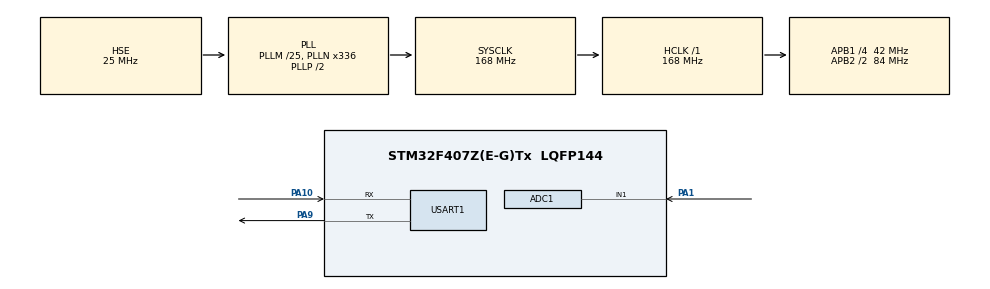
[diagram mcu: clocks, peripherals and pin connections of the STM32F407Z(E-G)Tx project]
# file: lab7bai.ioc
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ADC1.Channel-0\#ChannelRegularConversion=ADC_CHANNEL_1
ADC1.NbrOfConversionFlag=1
ADC1.Rank-0\#ChannelRegularConversion=1
ADC1.SamplingTime-0\#ChannelRegularConversion=ADC_SAMPLETIME_480CYCLES
ADC1.master=1
Mcu.Family=STM32F4
Mcu.Name=STM32F407Z(E-G)Tx
Mcu.Package=LQFP144
NVIC.PriorityGroup=NVIC_PRIORITYGROUP_4
PA1.Signal=ADCx_IN1
PA10.Mode=Asynchronous
PA10.Signal=USART1_RX
PA9.Mode=Asynchronous
PA9.Signal=USART1_TX
PH0-OSC_IN.Mode=HSE-External-Oscillator
PH0-OSC_IN.Signal=RCC_OSC_IN
PH1-OSC_OUT.Mode=HSE-External-Oscillator
PH1-OSC_OUT.Signal=RCC_OSC_OUT
ProjectManager.HeapSize=0x200
ProjectManager.StackSize=0x400
ProjectManager.TargetToolchain=STM32CubeIDE
RCC.48MHZClocksFreq_Value=84000000
RCC.AHBFreq_Value=168000000
RCC.APB1CLKDivider=RCC_HCLK_DIV4
RCC.APB1Freq_Value=42000000
RCC.APB1TimFreq_Value=84000000
RCC.APB2CLKDivider=RCC_HCLK_DIV2
RCC.APB2Freq_Value=84000000
RCC.APB2TimFreq_Value=168000000
RCC.CortexFreq_Value=168000000
RCC.HCLKFreq_Value=168000000
RCC.HSE_VALUE=25000000
RCC.HSI_VALUE=16000000
RCC.LSE_VALUE=32768
RCC.PLLM=25
RCC.PLLN=336
RCC.PLLSourceVirtual=RCC_PLLSOURCE_HSE
RCC.SYSCLKFreq_VALUE=168000000
RCC.SYSCLKSource=RCC_SYSCLKSOURCE_PLLCLK
RCC.VCOOutputFreq_Value=336000000
SH.ADCx_IN1.0=ADC1_IN1,IN1
USART1.VirtualMode=VM_ASYNC
board=custom

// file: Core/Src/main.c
/* USER CODE BEGIN Header */
/**
  ******************************************************************************
  * @file           : main.c
  * @brief          : Main program body
  ******************************************************************************
  * @attention
  *
  * Copyright (c) 2026 STMicroelectronics.
  * All rights reserved.
  *
  * This software is licensed under terms that can be found in the LICENSE file
  * in the root directory of this software component.
  * If no LICENSE file comes with this software, it is provided AS-IS.
  *
  ******************************************************************************
  */
/* USER CODE END Header */
#include "main.h"

/* USER CODE BEGIN Includes */
#include <stdio.h>
#include <string.h>
/* USER CODE END Includes */

/* USER CODE BEGIN PD */
  #define VREF       3.3f
  #define ADC_MAX    4095.0f
/* USER CODE END PD */

ADC_HandleTypeDef hadc1;

UART_HandleTypeDef huart1;

void SystemClock_Config(void);
static void MX_GPIO_Init(void);
static void MX_ADC1_Init(void);
static void MX_USART1_UART_Init(void);

/* USER CODE BEGIN 0 */
// Redirect printf to USART2
int __io_putchar(int ch)
{
    HAL_UART_Transmit(&huart1, (uint8_t *)&ch, 1, HAL_MAX_DELAY);
    return ch;
}
/* USER CODE END 0 */

int main(void)
{

  /* MCU Configuration--------------------------------------------------------*/

  /* Reset of all peripherals, Initializes the Flash interface and the Systick. */
	HAL_Init();

  /* Configure the system clock */
  SystemClock_Config();

  /* Initialize all configured peripherals */
  MX_GPIO_Init();
  MX_ADC1_Init();
  MX_USART1_UART_Init();
  /* USER CODE BEGIN 2 */
#define SCALE_INV  1.9960f
  uint32_t adc_raw = 0;
  float v_adc_in  = 0.0f;
  float v_bat     = 0.0f;

  // Voltage divider scale factor
  // With R1 = R2 = 1 MOhm, scale = R2/(R1+R2) = 0.5
  // So to recover original voltage: multiply by (R1+R2)/R2 = 2.0
  // ADC reference voltage

   // = (R1+R2)/R2, update in step 7#define SCALE_INV  2.0f
  /* USER CODE END 2 */

  /* Infinite loop */
  while (1)
  {

    /* USER CODE BEGIN 3 */
	  while (1)
	  {
	      // ===== STEPS 4, 8, 9 — Single conversion =====
	      HAL_ADC_Start(&hadc1);
	      HAL_ADC_PollForConversion(&hadc1, HAL_MAX_DELAY);
	      adc_raw = HAL_ADC_GetValue(&hadc1);
	      HAL_ADC_Stop(&hadc1);

	      v_adc_in = ((float)adc_raw / ADC_MAX) * VREF;
	      v_bat    = v_adc_in * SCALE_INV;  // <-- BREAKPOINT HERE for steps 4,8,9

	      // ===== STEPS 10, 11, 12 — Averaging (comment out above, uncomment this) =====

		  uint32_t sum = 0;
		    for (int i = 0; i < 10; i++)
		    {
		        HAL_ADC_Start(&hadc1);
		        HAL_ADC_PollForConversion(&hadc1, HAL_MAX_DELAY);
		        sum += HAL_ADC_GetValue(&hadc1);
		        HAL_ADC_Stop(&hadc1);
		        HAL_Delay(10);
		    }
		    adc_raw  = sum / 10;
		    v_adc_in = ((float)adc_raw / ADC_MAX) * VREF;
		    v_bat    = v_adc_in * SCALE_INV;

		    HAL_Delay(500);
	  }
  }
  /* USER CODE END 3 */
}

void SystemClock_Config(void)
{
  RCC_OscInitTypeDef RCC_OscInitStruct = {0};
  RCC_ClkInitTypeDef RCC_ClkInitStruct = {0};

  /** Configure the main internal regulator output voltage
  */
  __HAL_RCC_PWR_CLK_ENABLE();
  __HAL_PWR_VOLTAGESCALING_CONFIG(PWR_REGULATOR_VOLTAGE_SCALE1);

  /** Initializes the RCC Oscillators according to the specified parameters
  * in the RCC_OscInitTypeDef structure.
  */
  RCC_OscInitStruct.OscillatorType = RCC_OSCILLATORTYPE_HSE;
  RCC_OscInitStruct.HSEState = RCC_HSE_ON;
  RCC_OscInitStruct.PLL.PLLState = RCC_PLL_ON;
  RCC_OscInitStruct.PLL.PLLSource = RCC_PLLSOURCE_HSE;
  RCC_OscInitStruct.PLL.PLLM = 25;
  RCC_OscInitStruct.PLL.PLLN = 336;
  RCC_OscInitStruct.PLL.PLLP = RCC_PLLP_DIV2;
  RCC_OscInitStruct.PLL.PLLQ = 4;
  if (HAL_RCC_OscConfig(&RCC_OscInitStruct) != HAL_OK)
  {
    Error_Handler();
  }

  /** Initializes the CPU, AHB and APB buses clocks
  */
  RCC_ClkInitStruct.ClockType = RCC_CLOCKTYPE_HCLK|RCC_CLOCKTYPE_SYSCLK
                              |RCC_CLOCKTYPE_PCLK1|RCC_CLOCKTYPE_PCLK2;
  RCC_ClkInitStruct.SYSCLKSource = RCC_SYSCLKSOURCE_PLLCLK;
  RCC_ClkInitStruct.AHBCLKDivider = RCC_SYSCLK_DIV1;
  RCC_ClkInitStruct.APB1CLKDivider = RCC_HCLK_DIV4;
  RCC_ClkInitStruct.APB2CLKDivider = RCC_HCLK_DIV2;

  if (HAL_RCC_ClockConfig(&RCC_ClkInitStruct, FLASH_LATENCY_5) != HAL_OK)
  {
    Error_Handler();
  }
}

static void MX_ADC1_Init(void)
{

  ADC_ChannelConfTypeDef sConfig = {0};

  /** Configure the global features of the ADC (Clock, Resolution, Data Alignment and number of conversion)
  */
  hadc1.Instance = ADC1;
  hadc1.Init.ClockPrescaler = ADC_CLOCK_SYNC_PCLK_DIV4;
  hadc1.Init.Resolution = ADC_RESOLUTION_12B;
  hadc1.Init.ScanConvMode = DISABLE;
  hadc1.Init.ContinuousConvMode = DISABLE;
  hadc1.Init.DiscontinuousConvMode = DISABLE;
  hadc1.Init.ExternalTrigConvEdge = ADC_EXTERNALTRIGCONVEDGE_NONE;
  hadc1.Init.ExternalTrigConv = ADC_SOFTWARE_START;
  hadc1.Init.DataAlign = ADC_DATAALIGN_RIGHT;
  hadc1.Init.NbrOfConversion = 1;
  hadc1.Init.DMAContinuousRequests = DISABLE;
  hadc1.Init.EOCSelection = ADC_EOC_SINGLE_CONV;
  if (HAL_ADC_Init(&hadc1) != HAL_OK)
  {
    Error_Handler();
  }

  /** Configure for the selected ADC regular channel its corresponding rank in the sequencer and its sample time.
  */
  sConfig.Channel = ADC_CHANNEL_1;
  sConfig.Rank = 1;
  sConfig.SamplingTime = ADC_SAMPLETIME_480CYCLES;
  if (HAL_ADC_ConfigChannel(&hadc1, &sConfig) != HAL_OK)
  {
    Error_Handler();
  }

}

static void MX_USART1_UART_Init(void)
{

  huart1.Instance = USART1;
  huart1.Init.BaudRate = 115200;
  huart1.Init.WordLength = UART_WORDLENGTH_8B;
  huart1.Init.StopBits = UART_STOPBITS_1;
  huart1.Init.Parity = UART_PARITY_NONE;
  huart1.Init.Mode = UART_MODE_TX_RX;
  huart1.Init.HwFlowCtl = UART_HWCONTROL_NONE;
  huart1.Init.OverSampling = UART_OVERSAMPLING_16;
  if (HAL_UART_Init(&huart1) != HAL_OK)
  {
    Error_Handler();
  }

}

static void MX_GPIO_Init(void)
{

  /* GPIO Ports Clock Enable */
  __HAL_RCC_GPIOH_CLK_ENABLE();
  __HAL_RCC_GPIOA_CLK_ENABLE();

}

void Error_Handler(void)
{
  __disable_irq();
  while (1)
  {
  }
}
